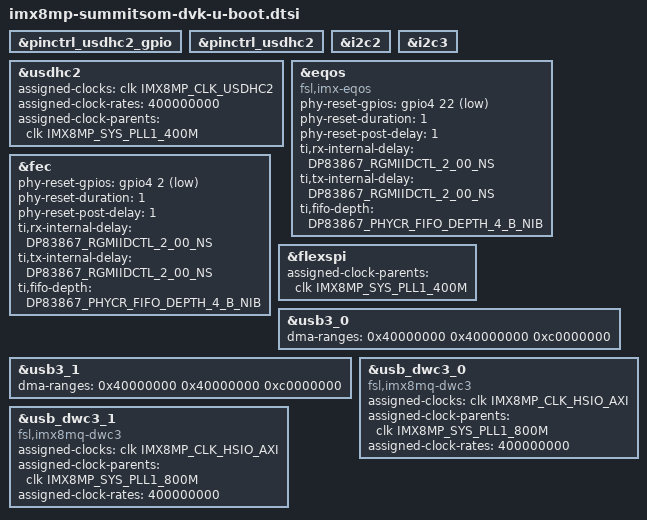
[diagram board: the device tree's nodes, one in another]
// SPDX-License-Identifier: GPL-2.0+
/*
 * Copyright 2021 Laird Connectivity
 */

#include "imx8mp-summitsom-u-boot.dtsi"

&pinctrl_usdhc2_gpio {
	u-boot,dm-spl;
};

&pinctrl_usdhc2 {
	u-boot,dm-spl;
};

&i2c2 {
	u-boot,dm-spl;
};

&i2c3 {
	u-boot,dm-spl;
};

&usdhc2 {
	u-boot,dm-spl;
	//sd-uhs-sdr104;
	//sd-uhs-ddr50;
	assigned-clocks = <&clk IMX8MP_CLK_USDHC2>;
	assigned-clock-rates = <400000000>;
	assigned-clock-parents = <&clk IMX8MP_SYS_PLL1_400M>;
};

&eqos {
	compatible = "fsl,imx-eqos";
	/delete-property/ assigned-clocks;
	/delete-property/ assigned-clock-parents;
	/delete-property/ assigned-clock-rates;

	phy-reset-gpios = <&gpio4 22 GPIO_ACTIVE_LOW>;
	phy-reset-duration = <1>;
	phy-reset-post-delay = <1>;

	ti,rx-internal-delay = <DP83867_RGMIIDCTL_2_00_NS>;
	ti,tx-internal-delay = <DP83867_RGMIIDCTL_2_00_NS>;
	ti,fifo-depth = <DP83867_PHYCR_FIFO_DEPTH_4_B_NIB>;
};

&fec {
	phy-reset-gpios = <&gpio4 2 GPIO_ACTIVE_LOW>;
	phy-reset-duration = <1>;
	phy-reset-post-delay = <1>;

	ti,rx-internal-delay = <DP83867_RGMIIDCTL_2_00_NS>;
	ti,tx-internal-delay = <DP83867_RGMIIDCTL_2_00_NS>;
	ti,fifo-depth = <DP83867_PHYCR_FIFO_DEPTH_4_B_NIB>;
};

&flexspi {
	assigned-clock-parents = <&clk IMX8MP_SYS_PLL1_400M>;
};

&usb3_0 {
	dma-ranges = <0x40000000 0x40000000 0xc0000000>;
	/delete-property/ power-domains;
};

&usb3_1 {
	dma-ranges = <0x40000000 0x40000000 0xc0000000>;
	/delete-property/ power-domains;
};

&usb_dwc3_0 {
	compatible = "fsl,imx8mq-dwc3", "snps,dwc3";
	assigned-clocks = <&clk IMX8MP_CLK_HSIO_AXI>;
	assigned-clock-parents = <&clk IMX8MP_SYS_PLL1_800M>;
	assigned-clock-rates = <400000000>;
};

&usb_dwc3_1 {
	compatible = "fsl,imx8mq-dwc3", "snps,dwc3";
	assigned-clocks = <&clk IMX8MP_CLK_HSIO_AXI>;
	assigned-clock-parents = <&clk IMX8MP_SYS_PLL1_800M>;
	assigned-clock-rates = <400000000>;
};
